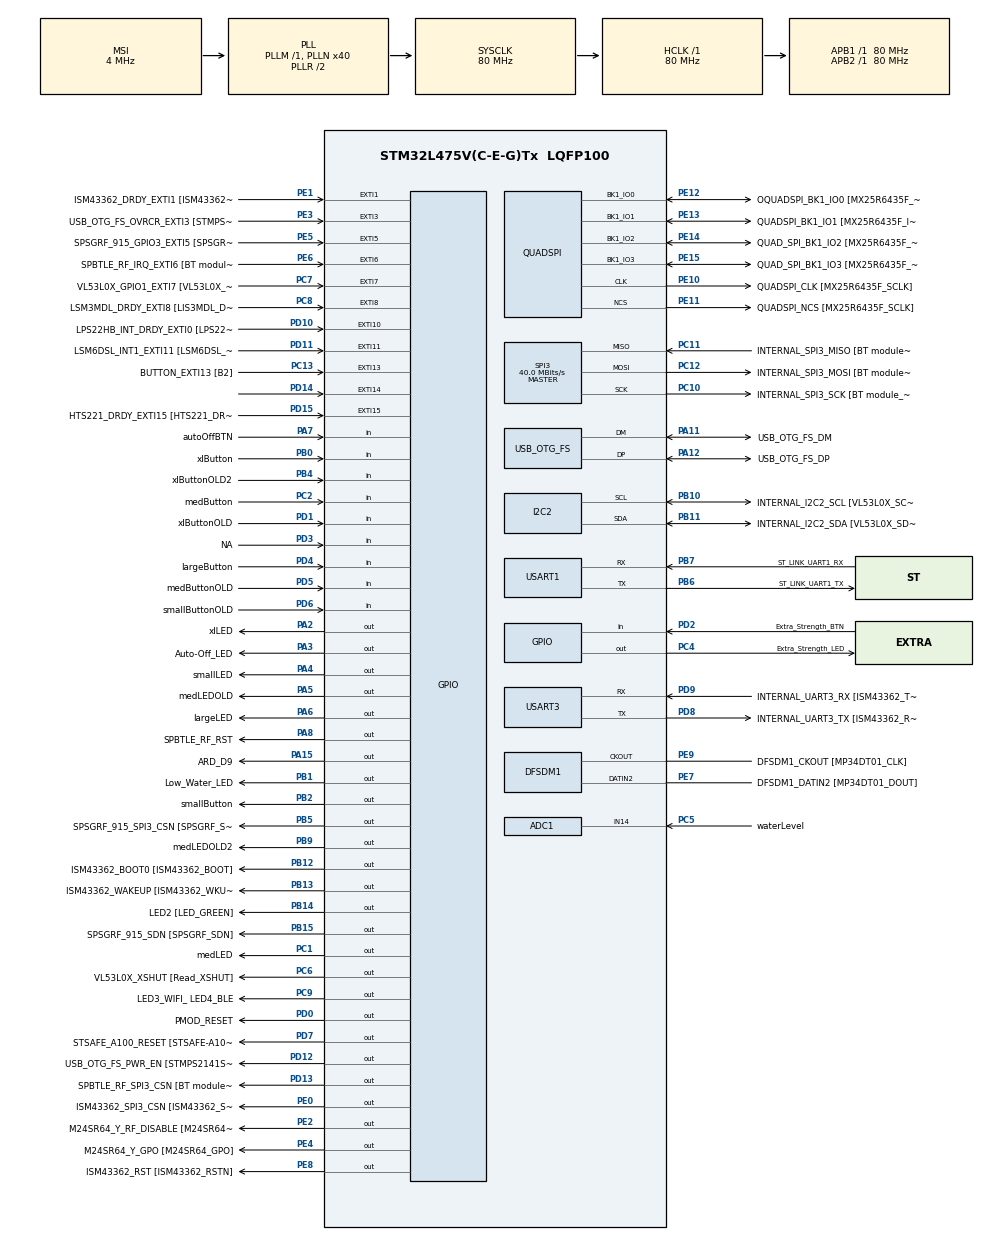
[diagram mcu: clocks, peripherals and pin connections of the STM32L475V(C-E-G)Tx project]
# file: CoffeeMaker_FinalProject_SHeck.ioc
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ADC1.Channel-0\#ChannelRegularConversion=ADC_CHANNEL_14
ADC1.NbrOfConversionFlag=1
ADC1.OffsetNumber-0\#ChannelRegularConversion=ADC_OFFSET_NONE
ADC1.Rank-0\#ChannelRegularConversion=1
ADC1.SamplingTime-0\#ChannelRegularConversion=ADC_SAMPLETIME_2CYCLES_5
ADC1.master=1
Mcu.Family=STM32L4
Mcu.Name=STM32L475V(C-E-G)Tx
Mcu.Package=LQFP100
NVIC.EXTI15_10_IRQn=true\:0\:0\:false\:false\:true\:true\:true
NVIC.EXTI9_5_IRQn=true\:0\:0\:false\:false\:true\:true\:true
NVIC.PriorityGroup=NVIC_PRIORITYGROUP_4
PA0.GPIO_Label=ARD_D1 [UART4_TX]
PA0.Signal=UART4_TX
PA1.GPIO_Label=ARD_D0 [UART4_RX]
PA1.Signal=UART4_RX
PA10.GPIO_Label=USB_OTG_FS_ID
PA10.Signal=USB_OTG_FS_ID
PA11.GPIO_Label=USB_OTG_FS_DM
PA11.Mode=Device_Only
PA11.Signal=USB_OTG_FS_DM
PA12.GPIO_Label=USB_OTG_FS_DP
PA12.Mode=Device_Only
PA12.Signal=USB_OTG_FS_DP
PA13\ (JTMS-SWDIO).GPIO_Label=SYS_JTMS_SWDIO
PA13\ (JTMS-SWDIO).Mode=Serial_Wire
PA13\ (JTMS-SWDIO).Signal=SYS_JTMS-SWDIO
PA14\ (JTCK-SWCLK).GPIO_Label=SYS_JTCK_SWCLK
PA14\ (JTCK-SWCLK).Mode=Serial_Wire
PA14\ (JTCK-SWCLK).Signal=SYS_JTCK-SWCLK
PA15\ (JTDI).GPIO_Label=ARD_D9
PA15\ (JTDI).Signal=GPIO_Output
PA2.GPIO_Label=xlLED
PA2.GPIO_ModeDefaultOutputPP=GPIO_MODE_OUTPUT_PP
PA2.GPIO_PuPd=GPIO_PULLUP
PA2.PinState=GPIO_PIN_RESET
PA2.Signal=GPIO_Output
PA3.GPIO_Label=Auto-Off_LED
PA3.Signal=GPIO_Output
PA4.GPIO_Label=smallLED
PA4.Signal=GPIO_Output
PA5.GPIO_Label=medLEDOLD
PA5.Signal=GPIO_Output
PA6.GPIO_Label=largeLED
PA6.Signal=GPIO_Output
PA7.GPIO_Label=autoOffBTN
PA7.Signal=GPIO_Input
PA8.GPIO_Label=SPBTLE_RF_RST
PA8.Signal=GPIO_Output
PA9.GPIO_Label=USB_OTG_FS_VBUS [STMPS2141STR_OUT]
PA9.Signal=USB_OTG_FS_VBUS
PB0.GPIO_Label=xlButton
PB0.Signal=GPIO_Input
PB1.GPIO_Label=Low_Water_LED
PB1.Signal=GPIO_Output
PB10.GPIO_Label=INTERNAL_I2C2_SCL [VL53L0X_SCL]
PB10.Mode=I2C
PB10.Signal=I2C2_SCL
PB11.GPIO_Label=INTERNAL_I2C2_SDA [VL53L0X_SDA]
PB11.Mode=I2C
PB11.Signal=I2C2_SDA
PB12.GPIO_Label=ISM43362_BOOT0 [ISM43362_BOOT]
PB12.Signal=GPIO_Output
PB13.GPIO_Label=ISM43362_WAKEUP [ISM43362_WKUP]
PB13.Signal=GPIO_Output
PB14.GPIO_Label=LED2 [LED_GREEN]
PB14.Signal=GPIO_Output
PB15.GPIO_Label=SPSGRF_915_SDN [SPSGRF_SDN]
PB15.Signal=GPIO_Output
PB2.GPIO_Label=smallButton
PB2.Signal=GPIO_Output
PB3\ (JTDO-TRACESWO).GPIO_Label=SYS_JTD0_SWO
PB3\ (JTDO-TRACESWO).Signal=SYS_JTDO-SWO
PB4\ (NJTRST).GPIO_Label=xlButtonOLD2
PB4\ (NJTRST).GPIO_PuPd=GPIO_NOPULL
PB4\ (NJTRST).Signal=GPIO_Input
PB5.GPIO_Label=SPSGRF_915_SPI3_CSN [SPSGRF_SPI_CS]
PB5.PinState=GPIO_PIN_SET
PB5.Signal=GPIO_Output
PB6.GPIO_Label=ST_LINK_UART1_TX
PB6.Mode=Asynchronous
PB6.Signal=USART1_TX
PB7.GPIO_Label=ST_LINK_UART1_RX
PB7.Mode=Asynchronous
PB7.Signal=USART1_RX
PB8.GPIO_Label=ARD_D15 [I2C1_SCL]
PB8.Signal=I2C1_SCL
PB9.GPIO_Label=medLEDOLD2
PB9.Signal=GPIO_Output
PC0.GPIO_Label=ARD_A5 [ADC]
PC0.Signal=ADCx_IN1
PC1.GPIO_Label=medLED
PC1.Signal=GPIO_Output
PC10.GPIO_Label=INTERNAL_SPI3_SCK [BT module_SPI_SCLK] [ISM43362_SCK]
PC10.Mode=Full_Duplex_Master
PC10.Signal=SPI3_SCK
PC11.GPIO_Label=INTERNAL_SPI3_MISO [BT module_SPI_MISO] [ISM43362_MISO]
PC11.Mode=Full_Duplex_Master
PC11.Signal=SPI3_MISO
PC12.GPIO_Label=INTERNAL_SPI3_MOSI [BT module_SPI_MOSI] [ISM43362_MOSI]
PC12.Mode=Full_Duplex_Master
PC12.Signal=SPI3_MOSI
PC13.GPIO_Label=BUTTON_EXTI13 [B2]
PC13.GPIO_ModeDefaultEXTI=GPIO_MODE_IT_FALLING
PC13.Signal=GPXTI13
PC14-OSC32_IN\ (PC14).Mode=LSE-External-Oscillator
PC14-OSC32_IN\ (PC14).Signal=RCC_OSC32_IN
PC15-OSC32_OUT\ (PC15).Mode=LSE-External-Oscillator
PC15-OSC32_OUT\ (PC15).Signal=RCC_OSC32_OUT
PC2.GPIO_Label=medButton
PC2.Signal=GPIO_Input
PC3.GPIO_Label=waterLevelOLD
PC3.Signal=ADCx_IN4
PC4.GPIO_Label=Extra_Strength_LED
PC4.Signal=GPIO_Output
PC5.GPIO_Label=waterLevel
PC5.Signal=ADCx_IN14
PC6.GPIO_Label=VL53L0X_XSHUT [Read_XSHUT]
PC6.Signal=GPIO_Output
PC7.GPIO_Label=VL53L0X_GPIO1_EXTI7 [VL53L0X_GPIO1]
PC7.Signal=GPXTI7
PC8.GPIO_Label=LSM3MDL_DRDY_EXTI8 [LIS3MDL_DRDY]
PC8.Signal=GPXTI8
PC9.GPIO_Label=LED3_WIFI_ LED4_BLE
PC9.Signal=GPIO_Output
PD0.GPIO_Label=PMOD_RESET
PD0.Signal=GPIO_Output
PD1.GPIO_Label=xlButtonOLD
PD1.GPIO_PuPd=GPIO_NOPULL
PD1.Signal=GPIO_Input
PD10.GPIO_Label=LPS22HB_INT_DRDY_EXTI0 [LPS22HB_INT_DRDY] 
PD10.Signal=GPXTI10
PD11.GPIO_Label=LSM6DSL_INT1_EXTI11 [LSM6DSL_INT1]
PD11.Signal=GPXTI11
PD12.GPIO_Label=USB_OTG_FS_PWR_EN [STMPS2141STR_EN]
PD12.Signal=GPIO_Output
PD13.GPIO_Label=SPBTLE_RF_SPI3_CSN [BT module_SPI_CS]
PD13.PinState=GPIO_PIN_SET
PD13.Signal=GPIO_Output
PD14.Signal=GPXTI14
PD15.GPIO_Label=HTS221_DRDY_EXTI15 [HTS221_DRDY]
PD15.Signal=GPXTI15
PD2.GPIO_Label=Extra_Strength_BTN
PD2.Signal=GPIO_Input
PD3.GPIO_Label=NA
PD3.Signal=GPIO_Input
PD4.GPIO_Label=largeButton
PD4.Signal=GPIO_Input
PD5.GPIO_Label=medButtonOLD
PD5.Signal=GPIO_Input
PD6.GPIO_Label=smallButtonOLD
PD6.GPIO_PuPd=GPIO_NOPULL
PD6.Signal=GPIO_Input
PD7.GPIO_Label=STSAFE_A100_RESET [STSAFE-A100_RESET]
PD7.Signal=GPIO_Output
PD8.GPIO_Label=INTERNAL_UART3_TX [ISM43362_RX]
PD8.Mode=Asynchronous
PD8.Signal=USART3_TX
PD9.GPIO_Label=INTERNAL_UART3_RX [ISM43362_TX]
PD9.Mode=Asynchronous
PD9.Signal=USART3_RX
PE0.GPIO_Label=ISM43362_SPI3_CSN [ISM43362_SSN]
PE0.PinState=GPIO_PIN_SET
PE0.Signal=GPIO_Output
PE1.GPIO_Label=ISM43362_DRDY_EXTI1 [ISM43362_DATARDY]
PE1.Signal=GPXTI1
PE10.GPIO_Label=QUADSPI_CLK [MX25R6435F_SCLK]
PE10.Mode=Single Bank
PE10.Signal=QUADSPI_CLK
PE11.GPIO_Label=QUADSPI_NCS [MX25R6435F_SCLK]
PE11.Mode=Single Bank
PE11.Signal=QUADSPI_NCS
PE12.GPIO_Label=OQUADSPI_BK1_IO0 [MX25R6435F_IO0]
PE12.Mode=Single Bank
PE12.Signal=QUADSPI_BK1_IO0
PE13.GPIO_Label=QUADSPI_BK1_IO1 [MX25R6435F_IO1]
PE13.Mode=Single Bank
PE13.Signal=QUADSPI_BK1_IO1
PE14.GPIO_Label=QUAD_SPI_BK1_IO2 [MX25R6435F_IO2]
PE14.Mode=Single Bank
PE14.Signal=QUADSPI_BK1_IO2
PE15.GPIO_Label=QUAD_SPI_BK1_IO3 [MX25R6435F_IO3]
PE15.Mode=Single Bank
PE15.Signal=QUADSPI_BK1_IO3
PE2.GPIO_Label=M24SR64_Y_RF_DISABLE [M24SR64_RFDIS]
PE2.Signal=GPIO_Output
PE3.GPIO_Label=USB_OTG_FS_OVRCR_EXTI3 [STMPS2141STR_FAULT]
PE3.Signal=GPXTI3
PE4.GPIO_Label=M24SR64_Y_GPO [M24SR64_GPO]
PE4.Signal=GPIO_Output
PE5.GPIO_Label=SPSGRF_915_GPIO3_EXTI5 [SPSGRF_GPIO_3]
PE5.Signal=GPXTI5
PE6.GPIO_Label=SPBTLE_RF_IRQ_EXTI6 [BT module_SPI_IRQ]
PE6.Signal=GPXTI6
PE7.GPIO_Label=DFSDM1_DATIN2 [MP34DT01_DOUT]
PE7.Signal=S_DATAIN2DFSDM1
PE8.GPIO_Label=ISM43362_RST [ISM43362_RSTN]
PE8.Signal=GPIO_Output
PE9.GPIO_Label=DFSDM1_CKOUT [MP34DT01_CLK]
PE9.Signal=S_CKOUTDFSDM1
ProjectManager.HeapSize=0x200
ProjectManager.StackSize=0x400
ProjectManager.TargetToolchain=STM32CubeIDE
RCC.ADCFreq_Value=48000000
RCC.AHBFreq_Value=80000000
RCC.APB1Freq_Value=80000000
RCC.APB1TimFreq_Value=80000000
RCC.APB2Freq_Value=80000000
RCC.APB2TimFreq_Value=80000000
RCC.CortexFreq_Value=80000000
RCC.HCLKFreq_Value=80000000
RCC.HSE_VALUE=8000000
RCC.HSI_VALUE=16000000
RCC.MSI_VALUE=4000000
RCC.PLLN=40
RCC.PLLSAI1N=24
RCC.SYSCLKFreq_VALUE=80000000
RCC.SYSCLKSource=RCC_SYSCLKSOURCE_PLLCLK
RCC.USBFreq_Value=48000000
RCC.VCOOutputFreq_Value=160000000
SH.ADCx_IN1.0=ADC1_IN1
SH.ADCx_IN14.0=ADC1_IN14,IN14-Single-Ended
SH.ADCx_IN4.0=ADC1_IN4
SH.S_CKOUTDFSDM1.0=DFSDM1_CKOUT,CKOUT
SH.S_CKOUTDFSDM1.1=DFSDM1_CKOUT,PDM_SPI_Input_from_ch12_and_Internal_Clock
SH.S_DATAIN2DFSDM1.0=DFSDM1_DATIN2,PDM_SPI_Input_from_ch12_and_Internal_Clock
SPI3.CalculateBaudRate=40.0 MBits/s
SPI3.Direction=SPI_DIRECTION_2LINES
SPI3.Mode=SPI_MODE_MASTER
SPI3.VirtualType=VM_MASTER
USART1.VirtualMode-Asynchronous=VM_ASYNC
USART3.VirtualMode-Asynchronous=VM_ASYNC
USB_OTG_FS.VirtualMode=Device_Only
board=B-L475E-IOT01A1

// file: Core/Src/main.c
/* USER CODE BEGIN Header */
/**
  ******************************************************************************
  * @file           : main.c
  * @brief          : Main program body
  ******************************************************************************
  * @attention
  *
  * <h2><center>&copy; Copyright (c) 2020 STMicroelectronics.
  * All rights reserved.</center></h2>
  *
  * This software component is licensed by ST under BSD 3-Clause license,
  * the "License"; You may not use this file except in compliance with the
  * License. You may obtain a copy of the License at:
  *                        opensource.org/licenses/BSD-3-Clause
  *
  ******************************************************************************
  */
/* USER CODE END Header */
#include "main.h"

/* USER CODE BEGIN Includes */
#include "stm32l4xx_hal.h"
#include "stm32l475e_iot01_tsensor.h"
#include "string.h"
#include "stdio.h"
/* USER CODE END Includes */

ADC_HandleTypeDef hadc1;

DFSDM_Channel_HandleTypeDef hdfsdm1_channel1;

I2C_HandleTypeDef hi2c2;

QSPI_HandleTypeDef hqspi;

SPI_HandleTypeDef hspi3;

UART_HandleTypeDef huart1;
UART_HandleTypeDef huart3;

PCD_HandleTypeDef hpcd_USB_OTG_FS;

/* USER CODE BEGIN PV */
int powerOn;
/* USER CODE END PV */

void SystemClock_Config(void);
static void MX_GPIO_Init(void);
static void MX_DFSDM1_Init(void);
static void MX_I2C2_Init(void);
static void MX_QUADSPI_Init(void);
static void MX_SPI3_Init(void);
static void MX_USART1_UART_Init(void);
static void MX_USART3_UART_Init(void);
static void MX_USB_OTG_FS_PCD_Init(void);
static void MX_ADC1_Init(void);
/* USER CODE BEGIN PFP */
void power_off (int LED2State);
/* USER CODE END PFP */

int main(void)
{

  /* MCU Configuration--------------------------------------------------------*/

  /* Reset of all peripherals, Initializes the Flash interface and the Systick. */
  HAL_Init();

  /* Configure the system clock */
  SystemClock_Config();

  /* Initialize all configured peripherals */
  MX_GPIO_Init();
  MX_DFSDM1_Init();
  MX_I2C2_Init();
  MX_QUADSPI_Init();
  MX_SPI3_Init();
  MX_USART1_UART_Init();
  MX_USART3_UART_Init();
  MX_USB_OTG_FS_PCD_Init();
  MX_ADC1_Init();
  /* USER CODE BEGIN 2 */
  int powerButton;
  int LED2State;
  int powerDownTimer;
  int powerDown_BTN;
  int extraStrengthButton;
  int extraStrengthLED;
  int autoOffLED;
  int autoOffBTN;
  int XL_BTN;
  int L_BTN;
  int M_BTN;
  int S_BTN;
  int halResult;
  int adcResult;
  float waterTemp;
  char *brew = "BREWING BEGAN\n";
  char *done = "BREWING COMPLETE\n";
  char *xstrength = "EXTRA STRENGTH SELECTED\n";
  char *normal = "NORMAL STRENGTH SELECTED\n";
  int index = 0;
  int xStronglen = strlen (xstrength);
  int brewlen = strlen (brew);
  int donelen = strlen (done);
  int normallen = strlen (normal);

  powerButton = 0;
  LED2State = 0;
  autoOffBTN = 0;
  autoOffLED = 0;
  powerDownTimer = 0;
  powerDown_BTN = 0;
  extraStrengthButton = 0;
  extraStrengthLED = 0;
  XL_BTN = 0;
  L_BTN = 0;
  M_BTN = 0;
  S_BTN = 0;
  halResult = 0;
  adcResult = 0;
  waterTemp = 0.0;

  /* USER CODE END 2 */

  /* Infinite loop */
  /* USER CODE BEGIN WHILE */
  BSP_TSENSOR_Init();
  while (1)
  {
	  /*
	   * Use User button from board as Power
	   * User LED2 from board as Power
	   * 1. Press button
	   * 	A. Power On
	   * 		i. Set variable
   * 		B. LED2 comes on
* 		2. Press Button
* 			A. Power off
* 				i. Set variable
* 			B. LED2 goes off
	   */

	  //Power the coffee maker up
	  powerButton = BSP_PB_GetState(BUTTON_EXTI13_Pin);
	  if (powerButton == 0)
	  {
		  BSP_LED_On(LED2_Pin);
		  LED2State = 1;
		  HAL_Delay(250);
	  }

	  //Power the coffee maker down
	  powerButton = BSP_PB_GetState(BUTTON_EXTI13_Pin);
	  if (powerButton == 0 && LED2State == 1)
	  {
		  power_off(LED2State);
	  }

	  //Make a Strong Brew cup
	  extraStrengthButton = HAL_GPIO_ReadPin(Extra_Strength_BTN_GPIO_Port, Extra_Strength_BTN_Pin);
	  if (extraStrengthButton == 1)
	  {
		  HAL_GPIO_WritePin(Extra_Strength_LED_GPIO_Port, Extra_Strength_LED_Pin, 1);
		  extraStrengthLED = 1;
		  HAL_Delay(250);
		  HAL_UART_Transmit(&huart1, (uint8_t*) &xstrength[index], 1, 0);
		  index++;
		  if (index == xStronglen)
		  {
			  index = 0;
		  }
		  HAL_Delay(10);
	  }

	  //Make a Normal Brew cup
	  extraStrengthButton = HAL_GPIO_ReadPin(Extra_Strength_BTN_GPIO_Port, Extra_Strength_BTN_Pin);
	  if (extraStrengthButton == 1 && extraStrengthLED == 1)
	  {
		  HAL_GPIO_WritePin(Extra_Strength_LED_GPIO_Port, Extra_Strength_LED_Pin, 0);
		  extraStrengthLED = 0;
		  HAL_Delay(250);
		  HAL_UART_Transmit(&huart1, (uint8_t *) &normal[index],1,0);
		  index++;
		  if (index == normallen)
		  {
			  index = 0;
		  }
		  HAL_Delay(10);
	  }

	  //Make a 12 Ounce cup
	  XL_BTN = HAL_GPIO_ReadPin(xlButton_GPIO_Port, xlButton_Pin);
	  if (XL_BTN == 1)
	  {
		  HAL_GPIO_WritePin(xlLED_GPIO_Port, xlLED_Pin, 1);
		  HAL_UART_Transmit(&huart1, (uint8_t *) &brew[index], 1, 0);
		  index++;
		  if (index == brewlen)
			  {
				  index = 0;
			  }
		  	  HAL_Delay(10);
		  HAL_Delay(12000);
		  HAL_GPIO_WritePin(xlLED_GPIO_Port, xlLED_Pin, 0);
		  XL_BTN = 0;
		  powerDownTimer = 0;
		  HAL_UART_Transmit(&huart1, (uint8_t *) &done[index], 1, 0);
		  index++;
		  if (index == donelen)
		  {
			  index = 0;
		  }
		  HAL_Delay(10);
	  }

	  // make a 10 Ounce cup
	  L_BTN = HAL_GPIO_ReadPin(largeButton_GPIO_Port, largeButton_Pin);
	  if (L_BTN == 1)
	  {
		  HAL_GPIO_WritePin(largeLED_GPIO_Port, largeLED_Pin, 1);
		  HAL_UART_Transmit(&huart1, (uint8_t *) &brew[index], 1, 0);
		  index++;
		  if (index == brewlen)
			  {
				  index = 0;
			  }
		  	  HAL_Delay(10);
		  HAL_Delay(10000);
		  HAL_GPIO_WritePin(largeLED_GPIO_Port, largeLED_Pin, 0);
		  L_BTN = 0;
		  powerDownTimer = 0;
		  HAL_UART_Transmit(&huart1, (uint8_t *) &done[index], 1, 0);
		  index++;
		  if (index == donelen)
		  {
			  index = 0;
		  }
		  HAL_Delay(10);
	  }

	  //Make an 8 Ounce cup
	  M_BTN = HAL_GPIO_ReadPin(medButton_GPIO_Port, medButton_Pin);
	  if (M_BTN == 1)
	  {
		  HAL_GPIO_WritePin(medLED_GPIO_Port, medLED_Pin, 1);
		  HAL_UART_Transmit(&huart1, (uint8_t *) &brew[index], 1, 0);
		  index++;
		  if (index == brewlen)
			  {
				  index = 0;
			  }
		  	  HAL_Delay(10);
		  HAL_Delay(8000);
		  HAL_GPIO_WritePin(medLED_GPIO_Port, medLED_Pin, 0);
		  M_BTN = 0;
		  powerDownTimer = 0;
		  HAL_UART_Transmit(&huart1, (uint8_t *) &done[index], 1, 0);
		  index++;
		  if (index == donelen)
		  {
			  index = 0;
		  }
		  HAL_Delay(10);
	  }

	  //Make a 6 Ounce cup
	  S_BTN = HAL_GPIO_ReadPin(smallButton_GPIO_Port, smallButton_Pin);
	  if (S_BTN == 1)
	  {
		  HAL_GPIO_WritePin(smallLED_GPIO_Port, smallLED_Pin, 1);
		  HAL_UART_Transmit(&huart1, (uint8_t *) &brew[index], 1, 0);
		  index++;
		  if (index == brewlen)
			  {
				  index = 0;
			  }
		  	  HAL_Delay(10);
		  HAL_Delay(6000);
		  HAL_GPIO_WritePin(smallLED_GPIO_Port, smallLED_Pin, 0);
		  S_BTN = 0;
		  powerDownTimer = 0;
		  HAL_UART_Transmit(&huart1, (uint8_t *) &done[index], 1, 0);
		  index++;
		  if (index == donelen)
		  {
			  index = 0;
		  }
		  HAL_Delay(10);
	  }

	  //Check water level
HAL_ADC_Start_IT (&hadc1);
halResult = HAL_ADC_PollForConversion(&hadc1, 100);
adcResult = HAL_ADC_GetValue(&hadc1);
if (adcResult >= 1934)
{
	HAL_GPIO_WritePin(Low_Water_LED_GPIO_Port, Low_Water_LED_Pin, 1);
	  HAL_GPIO_WritePin(xlLED_GPIO_Port, xlLED_Pin, 0);
	  HAL_GPIO_WritePin(largeLED_GPIO_Port, largeLED_Pin, 0);
	  HAL_GPIO_WritePin(medLED_GPIO_Port, medLED_Pin, 0);
	  HAL_GPIO_WritePin(smallLED_GPIO_Port, smallLED_Pin, 0);
}
else if (adcResult < 1934)
{
	HAL_GPIO_WritePin(Low_Water_LED_GPIO_Port, Low_Water_LED_Pin, 0);
}

//auto-off
powerDown_BTN = HAL_GPIO_ReadPin(autoOffBTN_GPIO_Port, Auto_Off_LED_Pin);
if (powerDown_BTN == 1)
{
	HAL_GPIO_WritePin(Auto_Off_LED_GPIO_Port, Auto_Off_LED_Pin, 1);
	autoOffLED = 1;
	powerDownTimer = HAL_GetTick();
	powerDown_BTN = 0;
	HAL_Delay(250);
	if (powerDownTimer == 50000)
	{
		power_off(LED2State);
	}
}
powerDown_BTN = HAL_GPIO_ReadPin(autoOffBTN_GPIO_Port, autoOffBTN_Pin);
if (powerDown_BTN == 1 && autoOffLED == 1)
{
	HAL_GPIO_WritePin(Auto_Off_LED_GPIO_Port, Auto_Off_LED_Pin, 0);
	autoOffLED = 0;
	HAL_Delay(250);
}

//water temperature
waterTemp = BSP_TSENSOR_ReadTemp();
printf ("waterTemp %f\n", waterTemp);

    /* USER CODE END WHILE */

  }
}

void SystemClock_Config(void)
{
  RCC_OscInitTypeDef RCC_OscInitStruct = {0};
  RCC_ClkInitTypeDef RCC_ClkInitStruct = {0};
  RCC_PeriphCLKInitTypeDef PeriphClkInit = {0};

  /** Configure LSE Drive Capability
  */
  HAL_PWR_EnableBkUpAccess();
  __HAL_RCC_LSEDRIVE_CONFIG(RCC_LSEDRIVE_LOW);
  /** Initializes the RCC Oscillators according to the specified parameters
  * in the RCC_OscInitTypeDef structure.
  */
  RCC_OscInitStruct.OscillatorType = RCC_OSCILLATORTYPE_LSE|RCC_OSCILLATORTYPE_MSI;
  RCC_OscInitStruct.LSEState = RCC_LSE_ON;
  RCC_OscInitStruct.MSIState = RCC_MSI_ON;
  RCC_OscInitStruct.MSICalibrationValue = 0;
  RCC_OscInitStruct.MSIClockRange = RCC_MSIRANGE_6;
  RCC_OscInitStruct.PLL.PLLState = RCC_PLL_ON;
  RCC_OscInitStruct.PLL.PLLSource = RCC_PLLSOURCE_MSI;
  RCC_OscInitStruct.PLL.PLLM = 1;
  RCC_OscInitStruct.PLL.PLLN = 40;
  RCC_OscInitStruct.PLL.PLLP = RCC_PLLP_DIV7;
  RCC_OscInitStruct.PLL.PLLQ = RCC_PLLQ_DIV2;
  RCC_OscInitStruct.PLL.PLLR = RCC_PLLR_DIV2;
  if (HAL_RCC_OscConfig(&RCC_OscInitStruct) != HAL_OK)
  {
    Error_Handler();
  }
  /** Initializes the CPU, AHB and APB buses clocks
  */
  RCC_ClkInitStruct.ClockType = RCC_CLOCKTYPE_HCLK|RCC_CLOCKTYPE_SYSCLK
                              |RCC_CLOCKTYPE_PCLK1|RCC_CLOCKTYPE_PCLK2;
  RCC_ClkInitStruct.SYSCLKSource = RCC_SYSCLKSOURCE_PLLCLK;
  RCC_ClkInitStruct.AHBCLKDivider = RCC_SYSCLK_DIV1;
  RCC_ClkInitStruct.APB1CLKDivider = RCC_HCLK_DIV1;
  RCC_ClkInitStruct.APB2CLKDivider = RCC_HCLK_DIV1;

  if (HAL_RCC_ClockConfig(&RCC_ClkInitStruct, FLASH_LATENCY_4) != HAL_OK)
  {
    Error_Handler();
  }
  PeriphClkInit.PeriphClockSelection = RCC_PERIPHCLK_USART1|RCC_PERIPHCLK_USART3
                              |RCC_PERIPHCLK_I2C2|RCC_PERIPHCLK_DFSDM1
                              |RCC_PERIPHCLK_USB|RCC_PERIPHCLK_ADC;
  PeriphClkInit.Usart1ClockSelection = RCC_USART1CLKSOURCE_PCLK2;
  PeriphClkInit.Usart3ClockSelection = RCC_USART3CLKSOURCE_PCLK1;
  PeriphClkInit.I2c2ClockSelection = RCC_I2C2CLKSOURCE_PCLK1;
  PeriphClkInit.AdcClockSelection = RCC_ADCCLKSOURCE_PLLSAI1;
  PeriphClkInit.Dfsdm1ClockSelection = RCC_DFSDM1CLKSOURCE_PCLK;
  PeriphClkInit.UsbClockSelection = RCC_USBCLKSOURCE_PLLSAI1;
  PeriphClkInit.PLLSAI1.PLLSAI1Source = RCC_PLLSOURCE_MSI;
  PeriphClkInit.PLLSAI1.PLLSAI1M = 1;
  PeriphClkInit.PLLSAI1.PLLSAI1N = 24;
  PeriphClkInit.PLLSAI1.PLLSAI1P = RCC_PLLP_DIV7;
  PeriphClkInit.PLLSAI1.PLLSAI1Q = RCC_PLLQ_DIV2;
  PeriphClkInit.PLLSAI1.PLLSAI1R = RCC_PLLR_DIV2;
  PeriphClkInit.PLLSAI1.PLLSAI1ClockOut = RCC_PLLSAI1_48M2CLK|RCC_PLLSAI1_ADC1CLK;
  if (HAL_RCCEx_PeriphCLKConfig(&PeriphClkInit) != HAL_OK)
  {
    Error_Handler();
  }
  /** Configure the main internal regulator output voltage
  */
  if (HAL_PWREx_ControlVoltageScaling(PWR_REGULATOR_VOLTAGE_SCALE1) != HAL_OK)
  {
    Error_Handler();
  }
  /** Enable MSI Auto calibration
  */
  HAL_RCCEx_EnableMSIPLLMode();
}

static void MX_ADC1_Init(void)
{

  ADC_MultiModeTypeDef multimode = {0};
  ADC_ChannelConfTypeDef sConfig = {0};

  /** Common config
  */
  hadc1.Instance = ADC1;
  hadc1.Init.ClockPrescaler = ADC_CLOCK_ASYNC_DIV1;
  hadc1.Init.Resolution = ADC_RESOLUTION_12B;
  hadc1.Init.DataAlign = ADC_DATAALIGN_RIGHT;
  hadc1.Init.ScanConvMode = ADC_SCAN_DISABLE;
  hadc1.Init.EOCSelection = ADC_EOC_SINGLE_CONV;
  hadc1.Init.LowPowerAutoWait = DISABLE;
  hadc1.Init.ContinuousConvMode = DISABLE;
  hadc1.Init.NbrOfConversion = 1;
  hadc1.Init.DiscontinuousConvMode = DISABLE;
  hadc1.Init.ExternalTrigConv = ADC_SOFTWARE_START;
  hadc1.Init.ExternalTrigConvEdge = ADC_EXTERNALTRIGCONVEDGE_NONE;
  hadc1.Init.DMAContinuousRequests = DISABLE;
  hadc1.Init.Overrun = ADC_OVR_DATA_PRESERVED;
  hadc1.Init.OversamplingMode = DISABLE;
  if (HAL_ADC_Init(&hadc1) != HAL_OK)
  {
    Error_Handler();
  }
  /** Configure the ADC multi-mode
  */
  multimode.Mode = ADC_MODE_INDEPENDENT;
  if (HAL_ADCEx_MultiModeConfigChannel(&hadc1, &multimode) != HAL_OK)
  {
    Error_Handler();
  }
  /** Configure Regular Channel
  */
  sConfig.Channel = ADC_CHANNEL_14;
  sConfig.Rank = ADC_REGULAR_RANK_1;
  sConfig.SamplingTime = ADC_SAMPLETIME_2CYCLES_5;
  sConfig.SingleDiff = ADC_SINGLE_ENDED;
  sConfig.OffsetNumber = ADC_OFFSET_NONE;
  sConfig.Offset = 0;
  if (HAL_ADC_ConfigChannel(&hadc1, &sConfig) != HAL_OK)
  {
    Error_Handler();
  }

}

static void MX_DFSDM1_Init(void)
{

  hdfsdm1_channel1.Instance = DFSDM1_Channel1;
  hdfsdm1_channel1.Init.OutputClock.Activation = ENABLE;
  hdfsdm1_channel1.Init.OutputClock.Selection = DFSDM_CHANNEL_OUTPUT_CLOCK_SYSTEM;
  hdfsdm1_channel1.Init.OutputClock.Divider = 2;
  hdfsdm1_channel1.Init.Input.Multiplexer = DFSDM_CHANNEL_EXTERNAL_INPUTS;
  hdfsdm1_channel1.Init.Input.DataPacking = DFSDM_CHANNEL_STANDARD_MODE;
  hdfsdm1_channel1.Init.Input.Pins = DFSDM_CHANNEL_FOLLOWING_CHANNEL_PINS;
  hdfsdm1_channel1.Init.SerialInterface.Type = DFSDM_CHANNEL_SPI_RISING;
  hdfsdm1_channel1.Init.SerialInterface.SpiClock = DFSDM_CHANNEL_SPI_CLOCK_INTERNAL;
  hdfsdm1_channel1.Init.Awd.FilterOrder = DFSDM_CHANNEL_FASTSINC_ORDER;
  hdfsdm1_channel1.Init.Awd.Oversampling = 1;
  hdfsdm1_channel1.Init.Offset = 0;
  hdfsdm1_channel1.Init.RightBitShift = 0x00;
  if (HAL_DFSDM_ChannelInit(&hdfsdm1_channel1) != HAL_OK)
  {
    Error_Handler();
  }

}

static void MX_I2C2_Init(void)
{

  hi2c2.Instance = I2C2;
  hi2c2.Init.Timing = 0x00000E14;
  hi2c2.Init.OwnAddress1 = 0;
  hi2c2.Init.AddressingMode = I2C_ADDRESSINGMODE_7BIT;
  hi2c2.Init.DualAddressMode = I2C_DUALADDRESS_DISABLE;
  hi2c2.Init.OwnAddress2 = 0;
  hi2c2.Init.OwnAddress2Masks = I2C_OA2_NOMASK;
  hi2c2.Init.GeneralCallMode = I2C_GENERALCALL_DISABLE;
  hi2c2.Init.NoStretchMode = I2C_NOSTRETCH_DISABLE;
  if (HAL_I2C_Init(&hi2c2) != HAL_OK)
  {
    Error_Handler();
  }
  /** Configure Analogue filter
  */
  if (HAL_I2CEx_ConfigAnalogFilter(&hi2c2, I2C_ANALOGFILTER_ENABLE) != HAL_OK)
  {
    Error_Handler();
  }
  /** Configure Digital filter
  */
  if (HAL_I2CEx_ConfigDigitalFilter(&hi2c2, 0) != HAL_OK)
  {
    Error_Handler();
  }

}

static void MX_QUADSPI_Init(void)
{

  /* QUADSPI parameter configuration*/
  hqspi.Instance = QUADSPI;
  hqspi.Init.ClockPrescaler = 255;
  hqspi.Init.FifoThreshold = 1;
  hqspi.Init.SampleShifting = QSPI_SAMPLE_SHIFTING_NONE;
  hqspi.Init.FlashSize = 1;
  hqspi.Init.ChipSelectHighTime = QSPI_CS_HIGH_TIME_1_CYCLE;
  hqspi.Init.ClockMode = QSPI_CLOCK_MODE_0;
  if (HAL_QSPI_Init(&hqspi) != HAL_OK)
  {
    Error_Handler();
  }

}

static void MX_SPI3_Init(void)
{

  /* SPI3 parameter configuration*/
  hspi3.Instance = SPI3;
  hspi3.Init.Mode = SPI_MODE_MASTER;
  hspi3.Init.Direction = SPI_DIRECTION_2LINES;
  hspi3.Init.DataSize = SPI_DATASIZE_4BIT;
  hspi3.Init.CLKPolarity = SPI_POLARITY_LOW;
  hspi3.Init.CLKPhase = SPI_PHASE_1EDGE;
  hspi3.Init.NSS = SPI_NSS_SOFT;
  hspi3.Init.BaudRatePrescaler = SPI_BAUDRATEPRESCALER_2;
  hspi3.Init.FirstBit = SPI_FIRSTBIT_MSB;
  hspi3.Init.TIMode = SPI_TIMODE_DISABLE;
  hspi3.Init.CRCCalculation = SPI_CRCCALCULATION_DISABLE;
  hspi3.Init.CRCPolynomial = 7;
  hspi3.Init.CRCLength = SPI_CRC_LENGTH_DATASIZE;
  hspi3.Init.NSSPMode = SPI_NSS_PULSE_ENABLE;
  if (HAL_SPI_Init(&hspi3) != HAL_OK)
  {
    Error_Handler();
  }

}

static void MX_USART1_UART_Init(void)
{

  huart1.Instance = USART1;
  huart1.Init.BaudRate = 115200;
  huart1.Init.WordLength = UART_WORDLENGTH_8B;
  huart1.Init.StopBits = UART_STOPBITS_1;
  huart1.Init.Parity = UART_PARITY_NONE;
  huart1.Init.Mode = UART_MODE_TX_RX;
  huart1.Init.HwFlowCtl = UART_HWCONTROL_NONE;
  huart1.Init.OverSampling = UART_OVERSAMPLING_16;
  huart1.Init.OneBitSampling = UART_ONE_BIT_SAMPLE_DISABLE;
  huart1.AdvancedInit.AdvFeatureInit = UART_ADVFEATURE_NO_INIT;
  if (HAL_UART_Init(&huart1) != HAL_OK)
  {
    Error_Handler();
  }

}

static void MX_USART3_UART_Init(void)
{

  huart3.Instance = USART3;
  huart3.Init.BaudRate = 115200;
  huart3.Init.WordLength = UART_WORDLENGTH_8B;
  huart3.Init.StopBits = UART_STOPBITS_1;
  huart3.Init.Parity = UART_PARITY_NONE;
  huart3.Init.Mode = UART_MODE_TX_RX;
  huart3.Init.HwFlowCtl = UART_HWCONTROL_NONE;
  huart3.Init.OverSampling = UART_OVERSAMPLING_16;
  huart3.Init.OneBitSampling = UART_ONE_BIT_SAMPLE_DISABLE;
  huart3.AdvancedInit.AdvFeatureInit = UART_ADVFEATURE_NO_INIT;
  if (HAL_UART_Init(&huart3) != HAL_OK)
  {
    Error_Handler();
  }

}

static void MX_USB_OTG_FS_PCD_Init(void)
{

  hpcd_USB_OTG_FS.Instance = USB_OTG_FS;
  hpcd_USB_OTG_FS.Init.dev_endpoints = 6;
  hpcd_USB_OTG_FS.Init.speed = PCD_SPEED_FULL;
  hpcd_USB_OTG_FS.Init.phy_itface = PCD_PHY_EMBEDDED;
  hpcd_USB_OTG_FS.Init.Sof_enable = DISABLE;
  hpcd_USB_OTG_FS.Init.low_power_enable = DISABLE;
  hpcd_USB_OTG_FS.Init.lpm_enable = DISABLE;
  hpcd_USB_OTG_FS.Init.battery_charging_enable = DISABLE;
  hpcd_USB_OTG_FS.Init.use_dedicated_ep1 = DISABLE;
  hpcd_USB_OTG_FS.Init.vbus_sensing_enable = DISABLE;
  if (HAL_PCD_Init(&hpcd_USB_OTG_FS) != HAL_OK)
  {
    Error_Handler();
  }

}

static void MX_GPIO_Init(void)
{
  GPIO_InitTypeDef GPIO_InitStruct = {0};

  /* GPIO Ports Clock Enable */
  __HAL_RCC_GPIOE_CLK_ENABLE();
  __HAL_RCC_GPIOC_CLK_ENABLE();
  __HAL_RCC_GPIOA_CLK_ENABLE();
  __HAL_RCC_GPIOB_CLK_ENABLE();
  __HAL_RCC_GPIOD_CLK_ENABLE();

  /*Configure GPIO pin Output Level */
  HAL_GPIO_WritePin(GPIOE, M24SR64_Y_RF_DISABLE_Pin|M24SR64_Y_GPO_Pin|ISM43362_RST_Pin, GPIO_PIN_RESET);

  /*Configure GPIO pin Output Level */
  HAL_GPIO_WritePin(GPIOC, medLED_Pin|Extra_Strength_LED_Pin|VL53L0X_XSHUT_Pin|LED3_WIFI__LED4_BLE_Pin, GPIO_PIN_RESET);

  /*Configure GPIO pin Output Level */
  HAL_GPIO_WritePin(GPIOA, xlLED_Pin|Auto_Off_LED_Pin|smallLED_Pin|medLEDOLD_Pin
                          |largeLED_Pin|SPBTLE_RF_RST_Pin|ARD_D9_Pin, GPIO_PIN_RESET);

  /*Configure GPIO pin Output Level */
  HAL_GPIO_WritePin(GPIOB, Low_Water_LED_Pin|smallButton_Pin|ISM43362_BOOT0_Pin|ISM43362_WAKEUP_Pin
                          |LED2_Pin|SPSGRF_915_SDN_Pin|medLEDOLD2_Pin, GPIO_PIN_RESET);

  /*Configure GPIO pin Output Level */
  HAL_GPIO_WritePin(GPIOD, USB_OTG_FS_PWR_EN_Pin|PMOD_RESET_Pin|STSAFE_A100_RESET_Pin, GPIO_PIN_RESET);

  /*Configure GPIO pin Output Level */
  HAL_GPIO_WritePin(SPBTLE_RF_SPI3_CSN_GPIO_Port, SPBTLE_RF_SPI3_CSN_Pin, GPIO_PIN_SET);

  /*Configure GPIO pin Output Level */
  HAL_GPIO_WritePin(SPSGRF_915_SPI3_CSN_GPIO_Port, SPSGRF_915_SPI3_CSN_Pin, GPIO_PIN_SET);

  /*Configure GPIO pin Output Level */
  HAL_GPIO_WritePin(ISM43362_SPI3_CSN_GPIO_Port, ISM43362_SPI3_CSN_Pin, GPIO_PIN_SET);

  /*Configure GPIO pins : M24SR64_Y_RF_DISABLE_Pin M24SR64_Y_GPO_Pin ISM43362_RST_Pin ISM43362_SPI3_CSN_Pin */
  GPIO_InitStruct.Pin = M24SR64_Y_RF_DISABLE_Pin|M24SR64_Y_GPO_Pin|ISM43362_RST_Pin|ISM43362_SPI3_CSN_Pin;
  GPIO_InitStruct.Mode = GPIO_MODE_OUTPUT_PP;
  GPIO_InitStruct.Pull = GPIO_NOPULL;
  GPIO_InitStruct.Speed = GPIO_SPEED_FREQ_LOW;
  HAL_GPIO_Init(GPIOE, &GPIO_InitStruct);

  /*Configure GPIO pins : USB_OTG_FS_OVRCR_EXTI3_Pin SPSGRF_915_GPIO3_EXTI5_Pin SPBTLE_RF_IRQ_EXTI6_Pin ISM43362_DRDY_EXTI1_Pin */
  GPIO_InitStruct.Pin = USB_OTG_FS_OVRCR_EXTI3_Pin|SPSGRF_915_GPIO3_EXTI5_Pin|SPBTLE_RF_IRQ_EXTI6_Pin|ISM43362_DRDY_EXTI1_Pin;
  GPIO_InitStruct.Mode = GPIO_MODE_IT_RISING;
  GPIO_InitStruct.Pull = GPIO_NOPULL;
  HAL_GPIO_Init(GPIOE, &GPIO_InitStruct);

  /*Configure GPIO pin : BUTTON_EXTI13_Pin */
  GPIO_InitStruct.Pin = BUTTON_EXTI13_Pin;
  GPIO_InitStruct.Mode = GPIO_MODE_IT_FALLING;
  GPIO_InitStruct.Pull = GPIO_NOPULL;
  HAL_GPIO_Init(BUTTON_EXTI13_GPIO_Port, &GPIO_InitStruct);

  /*Configure GPIO pins : medLED_Pin Extra_Strength_LED_Pin VL53L0X_XSHUT_Pin LED3_WIFI__LED4_BLE_Pin */
  GPIO_InitStruct.Pin = medLED_Pin|Extra_Strength_LED_Pin|VL53L0X_XSHUT_Pin|LED3_WIFI__LED4_BLE_Pin;
  GPIO_InitStruct.Mode = GPIO_MODE_OUTPUT_PP;
  GPIO_InitStruct.Pull = GPIO_NOPULL;
  GPIO_InitStruct.Speed = GPIO_SPEED_FREQ_LOW;
  HAL_GPIO_Init(GPIOC, &GPIO_InitStruct);

  /*Configure GPIO pin : medButton_Pin */
  GPIO_InitStruct.Pin = medButton_Pin;
  GPIO_InitStruct.Mode = GPIO_MODE_INPUT;
  GPIO_InitStruct.Pull = GPIO_NOPULL;
  HAL_GPIO_Init(medButton_GPIO_Port, &GPIO_InitStruct);

  /*Configure GPIO pins : ARD_D1_Pin ARD_D0_Pin */
  GPIO_InitStruct.Pin = ARD_D1_Pin|ARD_D0_Pin;
  GPIO_InitStruct.Mode = GPIO_MODE_AF_PP;
  GPIO_InitStruct.Pull = GPIO_NOPULL;
  GPIO_InitStruct.Speed = GPIO_SPEED_FREQ_VERY_HIGH;
  GPIO_InitStruct.Alternate = GPIO_AF8_UART4;
  HAL_GPIO_Init(GPIOA, &GPIO_InitStruct);

  /*Configure GPIO pin : xlLED_Pin */
  GPIO_InitStruct.Pin = xlLED_Pin;
  GPIO_InitStruct.Mode = GPIO_MODE_OUTPUT_PP;
  GPIO_InitStruct.Pull = GPIO_PULLUP;
  GPIO_InitStruct.Speed = GPIO_SPEED_FREQ_LOW;
  HAL_GPIO_Init(xlLED_GPIO_Port, &GPIO_InitStruct);

  /*Configure GPIO pins : Auto_Off_LED_Pin smallLED_Pin medLEDOLD_Pin largeLED_Pin
                           SPBTLE_RF_RST_Pin ARD_D9_Pin */
  GPIO_InitStruct.Pin = Auto_Off_LED_Pin|smallLED_Pin|medLEDOLD_Pin|largeLED_Pin
                          |SPBTLE_RF_RST_Pin|ARD_D9_Pin;
  GPIO_InitStruct.Mode = GPIO_MODE_OUTPUT_PP;
  GPIO_InitStruct.Pull = GPIO_NOPULL;
  GPIO_InitStruct.Speed = GPIO_SPEED_FREQ_LOW;
  HAL_GPIO_Init(GPIOA, &GPIO_InitStruct);

  /*Configure GPIO pin : autoOffBTN_Pin */
  GPIO_InitStruct.Pin = autoOffBTN_Pin;
  GPIO_InitStruct.Mode = GPIO_MODE_INPUT;
  GPIO_InitStruct.Pull = GPIO_NOPULL;
  HAL_GPIO_Init(autoOffBTN_GPIO_Port, &GPIO_InitStruct);

  /*Configure GPIO pins : xlButton_Pin xlButtonOLD2_Pin */
  GPIO_InitStruct.Pin = xlButton_Pin|xlButtonOLD2_Pin;
  GPIO_InitStruct.Mode = GPIO_MODE_INPUT;
  GPIO_InitStruct.Pull = GPIO_NOPULL;
  HAL_GPIO_Init(GPIOB, &GPIO_InitStruct);

  /*Configure GPIO pins : Low_Water_LED_Pin smallButton_Pin ISM43362_BOOT0_Pin ISM43362_WAKEUP_Pin
                           LED2_Pin SPSGRF_915_SDN_Pin SPSGRF_915_SPI3_CSN_Pin medLEDOLD2_Pin */
  GPIO_InitStruct.Pin = Low_Water_LED_Pin|smallButton_Pin|ISM43362_BOOT0_Pin|ISM43362_WAKEUP_Pin
                          |LED2_Pin|SPSGRF_915_SDN_Pin|SPSGRF_915_SPI3_CSN_Pin|medLEDOLD2_Pin;
  GPIO_InitStruct.Mode = GPIO_MODE_OUTPUT_PP;
  GPIO_InitStruct.Pull = GPIO_NOPULL;
  GPIO_InitStruct.Speed = GPIO_SPEED_FREQ_LOW;
  HAL_GPIO_Init(GPIOB, &GPIO_InitStruct);

  /*Configure GPIO pins : LPS22HB_INT_DRDY_EXTI0_Pin LSM6DSL_INT1_EXTI11_Pin PD14 HTS221_DRDY_EXTI15_Pin */
  GPIO_InitStruct.Pin = LPS22HB_INT_DRDY_EXTI0_Pin|LSM6DSL_INT1_EXTI11_Pin|GPIO_PIN_14|HTS221_DRDY_EXTI15_Pin;
  GPIO_InitStruct.Mode = GPIO_MODE_IT_RISING;
  GPIO_InitStruct.Pull = GPIO_NOPULL;
  HAL_GPIO_Init(GPIOD, &GPIO_InitStruct);

  /*Configure GPIO pins : USB_OTG_FS_PWR_EN_Pin SPBTLE_RF_SPI3_CSN_Pin PMOD_RESET_Pin STSAFE_A100_RESET_Pin */
  GPIO_InitStruct.Pin = USB_OTG_FS_PWR_EN_Pin|SPBTLE_RF_SPI3_CSN_Pin|PMOD_RESET_Pin|STSAFE_A100_RESET_Pin;
  GPIO_InitStruct.Mode = GPIO_MODE_OUTPUT_PP;
  GPIO_InitStruct.Pull = GPIO_NOPULL;
  GPIO_InitStruct.Speed = GPIO_SPEED_FREQ_LOW;
  HAL_GPIO_Init(GPIOD, &GPIO_InitStruct);

  /*Configure GPIO pins : VL53L0X_GPIO1_EXTI7_Pin LSM3MDL_DRDY_EXTI8_Pin */
  GPIO_InitStruct.Pin = VL53L0X_GPIO1_EXTI7_Pin|LSM3MDL_DRDY_EXTI8_Pin;
  GPIO_InitStruct.Mode = GPIO_MODE_IT_RISING;
  GPIO_InitStruct.Pull = GPIO_NOPULL;
  HAL_GPIO_Init(GPIOC, &GPIO_InitStruct);

  /*Configure GPIO pins : xlButtonOLD_Pin Extra_Strength_BTN_Pin NA_Pin largeButton_Pin
                           medButtonOLD_Pin smallButtonOLD_Pin */
  GPIO_InitStruct.Pin = xlButtonOLD_Pin|Extra_Strength_BTN_Pin|NA_Pin|largeButton_Pin
                          |medButtonOLD_Pin|smallButtonOLD_Pin;
  GPIO_InitStruct.Mode = GPIO_MODE_INPUT;
  GPIO_InitStruct.Pull = GPIO_NOPULL;
  HAL_GPIO_Init(GPIOD, &GPIO_InitStruct);

  /*Configure GPIO pin : ARD_D15_Pin */
  GPIO_InitStruct.Pin = ARD_D15_Pin;
  GPIO_InitStruct.Mode = GPIO_MODE_AF_OD;
  GPIO_InitStruct.Pull = GPIO_PULLUP;
  GPIO_InitStruct.Speed = GPIO_SPEED_FREQ_VERY_HIGH;
  GPIO_InitStruct.Alternate = GPIO_AF4_I2C1;
  HAL_GPIO_Init(ARD_D15_GPIO_Port, &GPIO_InitStruct);

  /* EXTI interrupt init*/
  HAL_NVIC_SetPriority(EXTI9_5_IRQn, 0, 0);
  HAL_NVIC_EnableIRQ(EXTI9_5_IRQn);

  HAL_NVIC_SetPriority(EXTI15_10_IRQn, 0, 0);
  HAL_NVIC_EnableIRQ(EXTI15_10_IRQn);

}

/* USER CODE BEGIN 4 */

//function to power down the coffee maker
void power_off (int LED2State)
{
	BSP_LED_Off(LED2);
	LED2State = 0;
	HAL_Delay(1000);
	HAL_GPIO_WritePin(Extra_Strength_LED_GPIO_Port, Extra_Strength_LED_Pin, 0);
	HAL_GPIO_WritePin(xlLED_GPIO_Port, xlLED_Pin, 0);
	HAL_GPIO_WritePin(largeLED_GPIO_Port, largeLED_Pin, 0);
	HAL_GPIO_WritePin(medLED_GPIO_Port, medLED_Pin, 0);
	HAL_GPIO_WritePin(smallLED_GPIO_Port, smallLED_Pin, 0);
	HAL_GPIO_WritePin(Auto_Off_LED_GPIO_Port, Auto_Off_LED_Pin, 0);
}
/* USER CODE END 4 */

void Error_Handler(void)
{
  __disable_irq();
  while (1)
  {
  }
}

/************************ (C) COPYRIGHT STMicroelectronics *****END OF FILE****/
